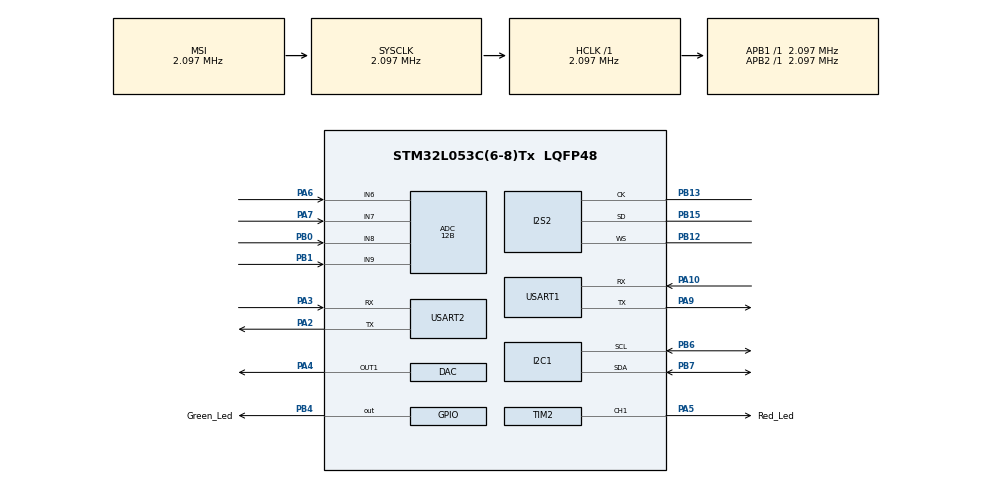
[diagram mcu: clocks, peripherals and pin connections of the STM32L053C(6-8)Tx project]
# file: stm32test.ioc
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ADC.ClockPrescaler=ADC_CLOCK_SYNC_PCLK_DIV1
ADC.ContinuousConvMode=DISABLE
ADC.DMAContinuousRequests=DISABLE
ADC.DataAlign=ADC_DATAALIGN_RIGHT
ADC.DiscontinuousConvMode=DISABLE
ADC.EOCSelection=ADC_EOC_SINGLE_CONV
ADC.EnableAnalogWatchDog=false
ADC.ExternalTrigConv=ADC_SOFTWARE_START
ADC.ExternalTrigConvEdge=ADC_EXTERNALTRIGCONVEDGE_NONE
ADC.LowPowerAutoPowerOff=DISABLE
ADC.LowPowerAutoWait=DISABLE
ADC.LowPowerFrequencyMode=DISABLE
ADC.Overrun=ADC_OVR_DATA_PRESERVED
ADC.OversamplingMode=DISABLE
ADC.Resolution=ADC_RESOLUTION_12B
ADC.SamplingTime=ADC_SAMPLETIME_1CYCLE_5
ADC.ScanConvMode=ADC_SCAN_DIRECTION_FORWARD
I2S2.ErrorAudioFreq=2.38 %
I2S2.Instance=SPI$Index
I2S2.RealAudioFreq=8.191 KHz
I2S2.VirtualMode=I2S_MODE_MASTER
Mcu.Family=STM32L0
Mcu.Name=STM32L053C(6-8)Tx
Mcu.Package=LQFP48
NVIC.USART1_IRQn=true\:0\:0\:false\:true\:true\:1\:true
NVIC.USART2_IRQn=true\:0\:0\:false\:true\:true\:2\:true
PA10.Mode=Asynchronous
PA10.Signal=USART1_RX
PA2.Mode=Asynchronous
PA2.Signal=USART2_TX
PA3.Mode=Asynchronous
PA3.Signal=USART2_RX
PA4.Signal=COMP_DAC1_group
PA5.GPIO_Label=Red_Led
PA5.Signal=S_TIM2_CH1
PA6.Mode=IN6
PA6.Signal=ADC_IN6
PA7.Mode=IN7
PA7.Signal=ADC_IN7
PA9.Mode=Asynchronous
PA9.Signal=USART1_TX
PB0.Mode=IN8
PB0.Signal=ADC_IN8
PB1.Mode=IN9
PB1.Signal=ADC_IN9
PB12.Mode=Half_Duplex_Master
PB12.Signal=I2S2_WS
PB13.Mode=Half_Duplex_Master
PB13.Signal=I2S2_CK
PB15.Mode=Half_Duplex_Master
PB15.Signal=I2S2_SD
PB4.GPIO_Label=Green_Led
PB4.Signal=GPIO_Output
PB6.Mode=I2C
PB6.Signal=I2C1_SCL
PB7.Mode=I2C
PB7.Signal=I2C1_SDA
ProjectManager.HeapSize=0x200
ProjectManager.StackSize=0x400
ProjectManager.TargetToolchain=Makefile
RCC.ADCFreq_Value=16000000
RCC.AHBFreq_Value=2097000
RCC.APB1Freq_Value=2097000
RCC.APB1TimFreq_Value=2097000
RCC.APB2Freq_Value=2097000
RCC.APB2TimFreq_Value=2097000
RCC.HSE_VALUE=8000000
RCC.HSI16_VALUE=16000000
RCC.HSI48_VALUE=48000000
RCC.HSI_VALUE=16000000
RCC.LSE_VALUE=32768
RCC.MSI_VALUE=2097000
RCC.SYSCLKFreq_VALUE=2097000
RCC.VCOOutputFreq_Value=48000000
SH.COMP_DAC1_group.0=DAC_OUT1,DAC_OUT1
SH.S_TIM2_CH1.0=TIM2_CH1,PWM Generation1 CH1
TIM2.Channel-PWM\ Generation1\ CH1=TIM_CHANNEL_1
TIM21.Channel-Forced\ Output2\ CH2=TIM_CHANNEL_2
TIM6.TIM_MasterOutputTrigger=TIM_TRGO_ENABLE
USART1.VirtualMode-Asynchronous=VM_ASYNC
USART2.VirtualMode-Asynchronous=VM_ASYNC
VP_TIM21_VS_ClockSourceINT.Mode=Internal
VP_TIM22_VS_ClockSourceINT.Mode=Internal
VP_TIM2_VS_ClockSourceINT.Mode=Internal
VP_TIM6_VS_ClockSourceINT.Mode=Enable_Timer
board=custom

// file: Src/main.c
/**
  ******************************************************************************
  * @file           : main.c
  * @brief          : Main program body
  ******************************************************************************
  ** This notice applies to any and all portions of this file
  * that are not between comment pairs USER CODE BEGIN and
  * USER CODE END. Other portions of this file, whether
  * inserted by the user or by software development tools
  * are owned by their respective copyright owners.
  *
  * COPYRIGHT(c) 2019 STMicroelectronics
  *
  * Redistribution and use in source and binary forms, with or without modification,
  * are permitted provided that the following conditions are met:
  *   1. Redistributions of source code must retain the above copyright notice,
  *      this list of conditions and the following disclaimer.
  *   2. Redistributions in binary form must reproduce the above copyright notice,
  *      this list of conditions and the following disclaimer in the documentation
  *      and/or other materials provided with the distribution.
  *   3. Neither the name of STMicroelectronics nor the names of its contributors
  *      may be used to endorse or promote products derived from this software
  *      without specific prior written permission.
  *
  * THIS SOFTWARE IS PROVIDED BY THE COPYRIGHT HOLDERS AND CONTRIBUTORS "AS IS"
  * AND ANY EXPRESS OR IMPLIED WARRANTIES, INCLUDING, BUT NOT LIMITED TO, THE
  * IMPLIED WARRANTIES OF MERCHANTABILITY AND FITNESS FOR A PARTICULAR PURPOSE ARE
  * DISCLAIMED. IN NO EVENT SHALL THE COPYRIGHT HOLDER OR CONTRIBUTORS BE LIABLE
  * FOR ANY DIRECT, INDIRECT, INCIDENTAL, SPECIAL, EXEMPLARY, OR CONSEQUENTIAL
  * DAMAGES (INCLUDING, BUT NOT LIMITED TO, PROCUREMENT OF SUBSTITUTE GOODS OR
  * SERVICES; LOSS OF USE, DATA, OR PROFITS; OR BUSINESS INTERRUPTION) HOWEVER
  * CAUSED AND ON ANY THEORY OF LIABILITY, WHETHER IN CONTRACT, STRICT LIABILITY,
  * OR TORT (INCLUDING NEGLIGENCE OR OTHERWISE) ARISING IN ANY WAY OUT OF THE USE
  * OF THIS SOFTWARE, EVEN IF ADVISED OF THE POSSIBILITY OF SUCH DAMAGE.
  *
  ******************************************************************************
  */
#include "main.h"
#include "stm32l0xx_hal.h"
#include "adc.h"
#include "dac.h"
#include "i2c.h"
#include "i2s.h"
#include "tim.h"
#include "usart.h"
#include "gpio.h"
#include "synth.h"

/* USER CODE BEGIN PV */
/* Private variables ---------------------------------------------------------*/

/* USER CODE END PV */

void SystemClock_Config(void);
static void MX_NVIC_Init(void);

/* USER CODE BEGIN PFP */
/* Private function prototypes -----------------------------------------------*/

/* USER CODE END PFP */

int main(void)
{

  /* MCU Configuration----------------------------------------------------------*/

  /* Reset of all peripherals, Initializes the Flash interface and the Systick. */
  HAL_Init();

  /* Configure the system clock */
  SystemClock_Config();

  /* Initialize all configured peripherals */
  MX_GPIO_Init();
  MX_TIM6_Init();
  MX_USART1_UART_Init();
  MX_USART2_UART_Init();
  MX_I2C1_Init();
  MX_ADC_Init();
  MX_DAC_Init();
  MX_TIM2_Init();
  MX_I2S2_Init();
  MX_TIM21_Init();
  MX_TIM22_Init();

  /* Initialize interrupts */
  MX_NVIC_Init();
  /* USER CODE BEGIN 2 */
  synth_init();
  /* USER CODE END 2 */

  /* Infinite loop */
  /* USER CODE BEGIN WHILE */
  int i;
  for (i = 0; i < BUFFER_SIZE; i++){
    uart_buffer[i] = 0;
  }
  //HAL_TIM_Base_Start(&htim2);
  HAL_TIM_PWM_Start(&htim2, TIM_CHANNEL_1);
  HAL_UART_Receive_IT(&huart1, (uint8_t *)&uart_buffer, 3); // lets get chars one by one
  while (true)
  {

    /* USER CODE END WHILE */
    /* USER CODE BEGIN 3 */
    mixer();

    int i;
    for(i = 0; i < 999999; i++){}

  }
  /* USER CODE END 3 */

}

void SystemClock_Config(void)
{

  RCC_OscInitTypeDef RCC_OscInitStruct;
  RCC_ClkInitTypeDef RCC_ClkInitStruct;
  RCC_PeriphCLKInitTypeDef PeriphClkInit;

  /**Configure the main internal regulator output voltage
  */
  __HAL_PWR_VOLTAGESCALING_CONFIG(PWR_REGULATOR_VOLTAGE_SCALE1);

  /**Initializes the CPU, AHB and APB busses clocks
  */
  RCC_OscInitStruct.OscillatorType = RCC_OSCILLATORTYPE_MSI;
  RCC_OscInitStruct.MSIState = RCC_MSI_ON;
  RCC_OscInitStruct.MSICalibrationValue = 0;
  RCC_OscInitStruct.MSIClockRange = RCC_MSIRANGE_5;
  RCC_OscInitStruct.PLL.PLLState = RCC_PLL_NONE;
  if (HAL_RCC_OscConfig(&RCC_OscInitStruct) != HAL_OK)
  {
    _Error_Handler(__FILE__, __LINE__);
  }

  /**Initializes the CPU, AHB and APB busses clocks
  */
  RCC_ClkInitStruct.ClockType = RCC_CLOCKTYPE_HCLK|RCC_CLOCKTYPE_SYSCLK
    |RCC_CLOCKTYPE_PCLK1|RCC_CLOCKTYPE_PCLK2;
  RCC_ClkInitStruct.SYSCLKSource = RCC_SYSCLKSOURCE_MSI;
  RCC_ClkInitStruct.AHBCLKDivider = RCC_SYSCLK_DIV1;
  RCC_ClkInitStruct.APB1CLKDivider = RCC_HCLK_DIV1;
  RCC_ClkInitStruct.APB2CLKDivider = RCC_HCLK_DIV1;

  if (HAL_RCC_ClockConfig(&RCC_ClkInitStruct, FLASH_LATENCY_0) != HAL_OK)
  {
    _Error_Handler(__FILE__, __LINE__);
  }

  PeriphClkInit.PeriphClockSelection = RCC_PERIPHCLK_USART1|RCC_PERIPHCLK_USART2
    |RCC_PERIPHCLK_I2C1;
  PeriphClkInit.Usart1ClockSelection = RCC_USART1CLKSOURCE_PCLK2;
  PeriphClkInit.Usart2ClockSelection = RCC_USART2CLKSOURCE_PCLK1;
  PeriphClkInit.I2c1ClockSelection = RCC_I2C1CLKSOURCE_PCLK1;
  if (HAL_RCCEx_PeriphCLKConfig(&PeriphClkInit) != HAL_OK)
  {
    _Error_Handler(__FILE__, __LINE__);
  }

  /**Configure the Systick interrupt time
  */
  HAL_SYSTICK_Config(HAL_RCC_GetHCLKFreq()/1000);

  /**Configure the Systick
  */
  HAL_SYSTICK_CLKSourceConfig(SYSTICK_CLKSOURCE_HCLK);

  /* SysTick_IRQn interrupt configuration */
  HAL_NVIC_SetPriority(SysTick_IRQn, 0, 0);
}

/**
 * @brief NVIC Configuration.
 * @retval None
 */
static void MX_NVIC_Init(void)
{
  /* USART1_IRQn interrupt configuration */
  HAL_NVIC_SetPriority(USART1_IRQn, 0, 0);
  HAL_NVIC_EnableIRQ(USART1_IRQn);
  /* USART2_IRQn interrupt configuration */
  HAL_NVIC_SetPriority(USART2_IRQn, 0, 0);
  HAL_NVIC_EnableIRQ(USART2_IRQn);
}

void _Error_Handler(char *file, int line)
{
  while(1)
  {
  }
}

/************************ (C) COPYRIGHT STMicroelectronics *****END OF FILE****/
